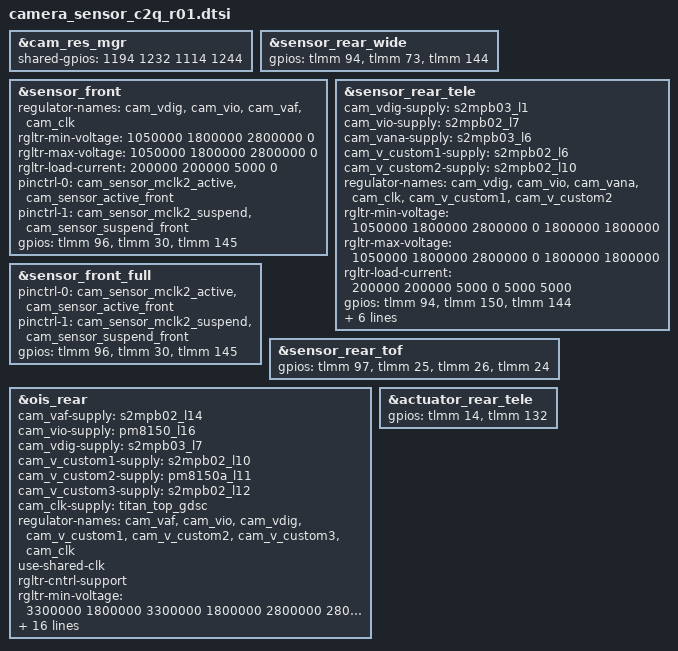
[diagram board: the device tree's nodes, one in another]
#include "camera_sensor_c2q_r00.dtsi"

&cam_res_mgr {
	shared-gpios = <1194 1232 1114 1244>;
};

&sensor_rear_wide {
	gpios = <&tlmm 94 0>,
		<&tlmm 73 0>,
		<&tlmm 144 0>;
};

&sensor_front {
	regulator-names = "cam_vdig", "cam_vio", "cam_vaf", "cam_clk";
	rgltr-min-voltage = <1050000 1800000 2800000 0>;
	rgltr-max-voltage = <1050000 1800000 2800000 0>;
	rgltr-load-current = <200000 200000 5000 0>;
	pinctrl-0 = <&cam_sensor_mclk2_active
			&cam_sensor_active_front>;
	pinctrl-1 = <&cam_sensor_mclk2_suspend
			&cam_sensor_suspend_front>;
	gpios = <&tlmm 96 0>,
		<&tlmm 30 0>,
		<&tlmm 145 0>;
};

&sensor_rear_tele {
	cam_vdig-supply = <&s2mpb03_l1>; /* VDD_TELECAM_1P05 */
	cam_vio-supply = <&s2mpb02_l7>; /* VDD_TELECAM_IO_1P8 */
	cam_vana-supply = <&s2mpb03_l6>; /* VDD_TELECAM_A2P9 */
	cam_v_custom1-supply = <&s2mpb02_l6>; /* VDD_VTCM_IO_1P8 */
	cam_v_custom2-supply = <&s2mpb02_l10>; /* VDD_TELECAM_AF_OIS_IO_1P8 */
	regulator-names = "cam_vdig", "cam_vio", "cam_vana", "cam_clk", "cam_v_custom1", "cam_v_custom2";
	rgltr-min-voltage = <1050000 1800000 2800000 0 1800000 1800000>;
	rgltr-max-voltage = <1050000 1800000 2800000 0 1800000 1800000>;
	rgltr-load-current = <200000 200000 5000 0 5000 5000>;
	gpios = <&tlmm 94 0>,
		<&tlmm 150 0>,
		<&tlmm 144 0>;
	gpio-reset = <1>;
	gpio-custom1 = <2>;
	gpio-req-tbl-num = <0 1 2>;
	gpio-req-tbl-flags = <1 0 0>;
	gpio-req-tbl-label = "CAMIF_MCLK0",
				"CAM_RESET0",
				"MAINCAM_LDO_EN";
};

&sensor_front_full {
	pinctrl-0 = <&cam_sensor_mclk2_active
			&cam_sensor_active_front>;
	pinctrl-1 = <&cam_sensor_mclk2_suspend
			&cam_sensor_suspend_front>;
	gpios = <&tlmm 96 0>,
		<&tlmm 30 0>,
		<&tlmm 145 0>;
};

&sensor_rear_tof {
	gpios = <&tlmm 97 0>,
		<&tlmm 25 0>,
		<&tlmm 26 0>,
		<&tlmm 24 0>;
};

&ois_rear {
		cam_vaf-supply = <&s2mpb02_l14>; /* VDD_MAINCAM_AF_3P3 */
		cam_vio-supply = <&pm8150_l16>; /* VDD_OIS_MCU_1P8 */
		cam_vdig-supply = <&s2mpb03_l7>; /* VDD_MAINCAM_OIS_3P3 */
		cam_v_custom1-supply = <&s2mpb02_l10>; /* VDD_TELECAM_AF_OIS_IO_1P8 */
		cam_v_custom2-supply = <&pm8150a_l11>; /* VDD_TELECAM_AF_OIS_VM_2P8 */
		cam_v_custom3-supply = <&s2mpb02_l12>; /* VDD_TELECAM_AF_OIS_A2P8 */
                cam_clk-supply = <&titan_top_gdsc>;
		regulator-names = "cam_vaf", "cam_vio", "cam_vdig", "cam_v_custom1", "cam_v_custom2", "cam_v_custom3", "cam_clk";
                use-shared-clk;
		rgltr-cntrl-support;
		rgltr-min-voltage = <3300000 1800000 3300000 1800000 2800000 2800000 0>;
		rgltr-max-voltage = <3300000 1800000 3300000 1800000 2800000 2800000 0>;
		rgltr-load-current = <5000 5000 5000 5000 5000 5000 0>;
		gpio-no-mux = <0>;
		gpios = <&tlmm 94 0>,  // MCLK0
		        <&tlmm 14 0>,  // RESET
			<&tlmm 118 0>, // BOOT0
			<&tlmm 132 0>; // TELECAM_OIS_RST
		gpio-reset = <1>;
		gpio-custom1 = <2>;
		gpio-custom2 = <3>;
		gpio-req-tbl-num = <0 1 2 3>;
		gpio-req-tbl-flags = <1 0 0 0>;
		gpio-req-tbl-label = "CAMIF_MCLK0", "MCU_RESET0", "MCU_BOOT0", "MCU_RESET1";
		status = "ok";

		clocks = <&clock_camcc CAM_CC_MCLK0_CLK>;
                clock-names = "cam_clk";
                clock-cntl-level = "turbo";
                clock-rates = <19200000>;
};

&actuator_rear_tele {
	gpios = <&tlmm 14 0>, // RESET
		<&tlmm 132 0>; // TELECAM_OIS_RST
};

